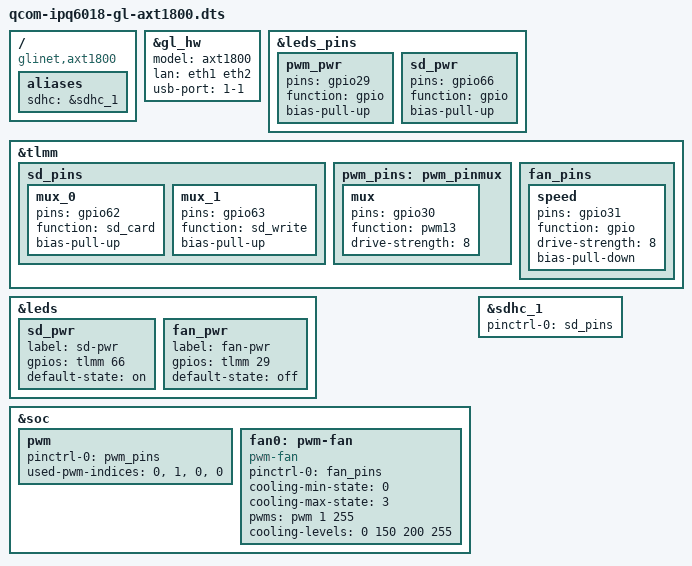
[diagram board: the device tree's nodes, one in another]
/dts-v1/;
/*
 * Copyright (c) 2019, The Linux Foundation. All rights reserved.
 *
 * Permission to use, copy, modify, and/or distribute this software for any
 * purpose with or without fee is hereby granted, provided that the above
 * copyright notice and this permission notice appear in all copies.
 *
 * THE SOFTWARE IS PROVIDED "AS IS" AND THE AUTHOR DISCLAIMS ALL WARRANTIES
 * WITH REGARD TO THIS SOFTWARE INCLUDING ALL IMPLIED WARRANTIES OF
 * MERCHANTABILITY AND FITNESS. IN NO EVENT SHALL THE AUTHOR BE LIABLE FOR
 * ANY SPECIAL, DIRECT, INDIRECT, OR CONSEQUENTIAL DAMAGES OR ANY DAMAGES
 * WHATSOEVER RESULTING FROM LOSS OF USE, DATA OR PROFITS, WHETHER IN AN
 * ACTION OF CONTRACT, NEGLIGENCE OR OTHER TORTIOUS ACTION, ARISING OUT OF
 * OR IN CONNECTION WITH THE USE OR PERFORMANCE OF THIS SOFTWARE.
 */

#include "qcom-ipq6018-gl-ax1800.dtsi"

/ {
	compatible = "glinet,axt1800", "qcom,ipq6018-cp03", "qcom,ipq6018";

	aliases {
		sdhc = &sdhc_1;
	};
};

&gl_hw {
	model = "axt1800";
	lan = "eth1 eth2";
	usb-port = "1-1";
};

&leds_pins {
	pwm_pwr {
		pins = "gpio29";
		function = "gpio";
		bias-pull-up;
	};
	sd_pwr {
		pins = "gpio66";
		function = "gpio";
		bias-pull-up;
	};
};

&tlmm {
	sd_pins: sd_pins {
		mux_0 {
			pins = "gpio62";
			function = "sd_card";
			bias-pull-up;
		};
		mux_1 {
			pins = "gpio63";
			function = "sd_write";
			bias-pull-up;
		};
	};

	pwm_pins: pwm_pinmux {
		mux {
			pins = "gpio30";
			function = "pwm13";
			drive-strength = <8>;
		};
	};

	fan_pins: fan_pins {
		speed {
			pins = "gpio31";
			function = "gpio";
			drive-strength = <8>;
			bias-pull-down;
		};
	};
};

&leds {
	sd_pwr {
		label = "sd-pwr";
		gpios = <&tlmm 66 GPIO_ACTIVE_HIGH>;
		default-state = "on";
	};

	fan_pwr {
		label = "fan-pwr";
		gpios = <&tlmm 29 GPIO_ACTIVE_HIGH>;
		default-state = "off";
	};
};

&soc {
	pwm:pwm {
		#pwm-cells = <2>;
		pinctrl-0 = <&pwm_pins>;
		pinctrl-names = "default";
		used-pwm-indices = <0>, <1>, <0>, <0>;
		status = "ok";
	};

	fan0: pwm-fan {
		compatible = "pwm-fan";
		pinctrl-0 = <&fan_pins>;
		cooling-min-state = <0>;
		cooling-max-state = <3>;
		#cooling-cells = <2>;
		pwms = <&pwm 1 255>;
		cooling-levels = <0 150 200 255>;
	};
};

&sdhc_1 {
	pinctrl-0 = <&sd_pins>;
	pinctrl-names = "default";
	status = "ok";
};
